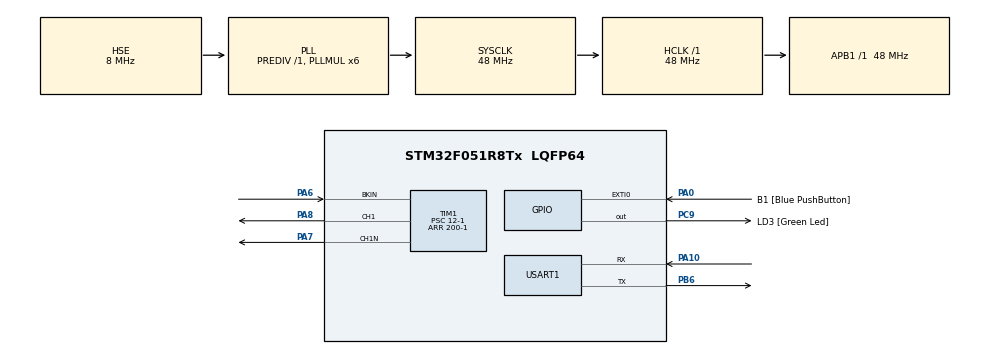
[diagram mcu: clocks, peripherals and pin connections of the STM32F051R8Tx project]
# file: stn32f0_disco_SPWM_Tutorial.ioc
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Mcu.Family=STM32F0
Mcu.Name=STM32F051R8Tx
Mcu.Package=LQFP64
NVIC.TIM1_BRK_UP_TRG_COM_IRQn=true\:0\:0\:false\:false\:true\:true\:true
PA0.GPIO_Label=B1 [Blue PushButton]
PA0.GPIO_ModeDefaultEXTI=GPIO_MODE_EVT_RISING
PA0.Signal=GPXTI0
PA10.Mode=Asynchronous
PA10.Signal=USART1_RX
PA13.GPIO_Label=SWDIO
PA13.Mode=Serial_Wire
PA13.Signal=SYS_SWDIO
PA14.GPIO_Label=SWCLK
PA14.Mode=Serial_Wire
PA14.Signal=SYS_SWCLK
PA6.Mode=Activate-Break-Input
PA6.Signal=TIM1_BKIN
PA7.Mode=PWM Generation1 CH1 CH1N
PA7.Signal=TIM1_CH1N
PA8.Signal=S_TIM1_CH1
PB6.Mode=Asynchronous
PB6.Signal=USART1_TX
PC9.GPIO_Label=LD3 [Green Led]
PC9.Signal=GPIO_Output
PF0-OSC_IN.Mode=HSE-External-Oscillator
PF0-OSC_IN.Signal=RCC_OSC_IN
PF1-OSC_OUT.Mode=HSE-External-Oscillator
PF1-OSC_OUT.Signal=RCC_OSC_OUT
ProjectManager.HeapSize=0x200
ProjectManager.StackSize=0x400
ProjectManager.TargetToolchain=STM32CubeIDE
RCC.AHBFreq_Value=48000000
RCC.APB1Freq_Value=48000000
RCC.APB1TimFreq_Value=48000000
RCC.HCLKFreq_Value=48000000
RCC.PLLMUL=RCC_PLL_MUL6
RCC.PLLSourceVirtual=RCC_PLLSOURCE_HSE
RCC.SYSCLKFreq_VALUE=48000000
RCC.SYSCLKSource=RCC_SYSCLKSOURCE_PLLCLK
SH.S_TIM1_CH1.0=TIM1_CH1,PWM Generation1 CH1 CH1N
TIM1.AutoReloadPreload=TIM_AUTORELOAD_PRELOAD_ENABLE
TIM1.AutomaticOutput=TIM_AUTOMATICOUTPUT_ENABLE
TIM1.Channel-PWM\ Generation1\ CH1\ CH1N=TIM_CHANNEL_1
TIM1.CounterMode=TIM_COUNTERMODE_CENTERALIGNED1
TIM1.DeadTime=10
TIM1.Period=200-1
TIM1.Prescaler=12-1
TIM1.TIM_MasterOutputTrigger=TIM_TRGO_RESET
TIM1.TIM_MasterSlaveMode=TIM_MASTERSLAVEMODE_DISABLE
USART1.VirtualMode-Asynchronous=VM_ASYNC
VP_TIM1_VS_ClockSourceINT.Mode=Internal
board=STM32F0DISCOVERY

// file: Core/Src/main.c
/* USER CODE BEGIN Header */
/**
  ******************************************************************************
  * @file           : main.c
  * @brief          : Main program body
  ******************************************************************************
  * @attention
  *
  * <h2><center>&copy; Copyright (c) 2023 STMicroelectronics.
  * All rights reserved.</center></h2>
  *
  * This software component is licensed by ST under BSD 3-Clause license,
  * the "License"; You may not use this file except in compliance with the
  * License. You may obtain a copy of the License at:
  *                        opensource.org/licenses/BSD-3-Clause
  *
  ******************************************************************************
  */
/* USER CODE END Header */

#include "main.h"
#include "tim.h"
#include "usart.h"
#include "gpio.h"

/* USER CODE BEGIN Includes */
#include "math.h"
#define PI	3.14
/* USER CODE END Includes */

/* USER CODE BEGIN PTD */
#define MAX_PULSE	200	/*	Fsw = 10KHz Fo = 50Hz
/* USER CODE END PTD */

/* USER CODE BEGIN PV */
uint16_t duty = 0;
uint16_t cur_pulse = 0;
float angle_step_rate = ((float)360.0/400);
uint16_t sin_duty[400] = {0};
/* USER CODE END PV */

void SystemClock_Config(void);

/* USER CODE BEGIN 0 */
void create_sin_table(uint16_t t[]){
	int i;
	for(i=0;i<MAX_PULSE;i++){
		/*	ARR = 200 for 10KHz freq	*/
		t[i] = (uint16_t)(200/2)+((99)*sin((PI/180)*angle_step_rate*i));
	}
}
/* USER CODE END 0 */

int main(void)
{

  /* MCU Configuration--------------------------------------------------------*/

  /* Reset of all peripherals, Initializes the Flash interface and the Systick. */
  HAL_Init();

  /* Configure the system clock */
  SystemClock_Config();

  /* Initialize all configured peripherals */
  MX_GPIO_Init();
  MX_TIM1_Init();
  MX_USART1_UART_Init();
  /* USER CODE BEGIN 2 */
//  HAL_TIMEx_PWMN_Start_IT(&htim1, TIM_CHANNEL_1);
  create_sin_table(sin_duty);
  HAL_TIM_Base_Start_IT(&htim1);
  HAL_TIM_PWM_Start(&htim1, TIM_CHANNEL_1);
  HAL_TIMEx_PWMN_Start(&htim1, TIM_CHANNEL_1);
  __HAL_TIM_SET_COMPARE(&htim1,TIM_CHANNEL_1,10);

  /* USER CODE END 2 */

  /* Infinite loop */
  while (1)
  {

  }
}

void SystemClock_Config(void)
{
  RCC_OscInitTypeDef RCC_OscInitStruct = {0};
  RCC_ClkInitTypeDef RCC_ClkInitStruct = {0};
  RCC_PeriphCLKInitTypeDef PeriphClkInit = {0};

  /** Initializes the CPU, AHB and APB busses clocks
  */
  RCC_OscInitStruct.OscillatorType = RCC_OSCILLATORTYPE_HSE;
  RCC_OscInitStruct.HSEState = RCC_HSE_ON;
  RCC_OscInitStruct.PLL.PLLState = RCC_PLL_ON;
  RCC_OscInitStruct.PLL.PLLSource = RCC_PLLSOURCE_HSE;
  RCC_OscInitStruct.PLL.PLLMUL = RCC_PLL_MUL6;
  RCC_OscInitStruct.PLL.PREDIV = RCC_PREDIV_DIV1;
  if (HAL_RCC_OscConfig(&RCC_OscInitStruct) != HAL_OK)
  {
    Error_Handler();
  }
  /** Initializes the CPU, AHB and APB busses clocks
  */
  RCC_ClkInitStruct.ClockType = RCC_CLOCKTYPE_HCLK|RCC_CLOCKTYPE_SYSCLK
                              |RCC_CLOCKTYPE_PCLK1;
  RCC_ClkInitStruct.SYSCLKSource = RCC_SYSCLKSOURCE_PLLCLK;
  RCC_ClkInitStruct.AHBCLKDivider = RCC_SYSCLK_DIV1;
  RCC_ClkInitStruct.APB1CLKDivider = RCC_HCLK_DIV1;

  if (HAL_RCC_ClockConfig(&RCC_ClkInitStruct, FLASH_LATENCY_1) != HAL_OK)
  {
    Error_Handler();
  }
  PeriphClkInit.PeriphClockSelection = RCC_PERIPHCLK_USART1;
  PeriphClkInit.Usart1ClockSelection = RCC_USART1CLKSOURCE_PCLK1;
  if (HAL_RCCEx_PeriphCLKConfig(&PeriphClkInit) != HAL_OK)
  {
    Error_Handler();
  }
}

void Error_Handler(void)
{
}

/************************ (C) COPYRIGHT STMicroelectronics *****END OF FILE****/
